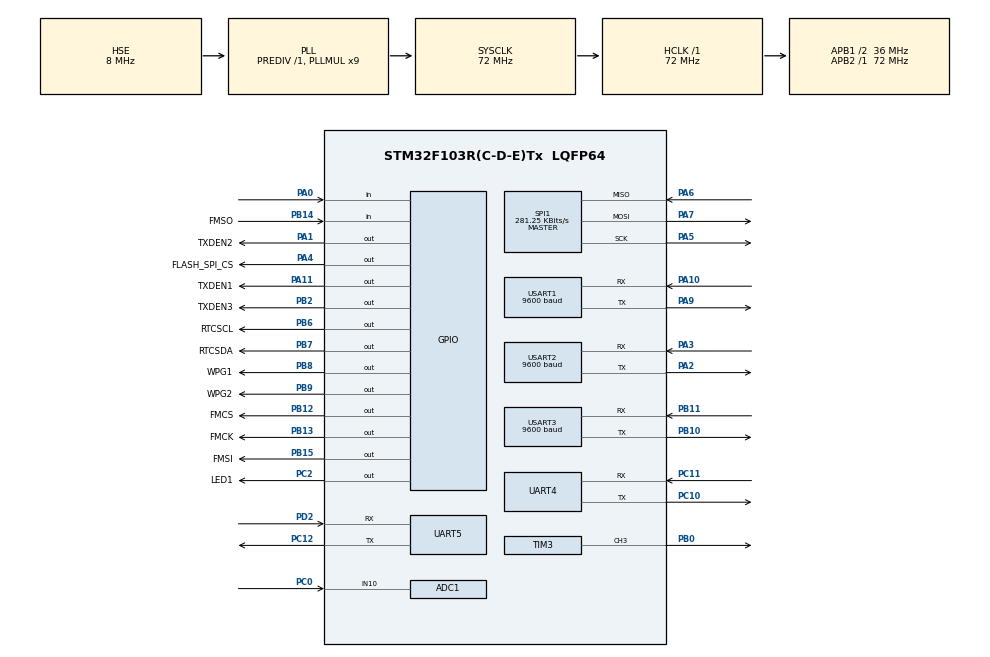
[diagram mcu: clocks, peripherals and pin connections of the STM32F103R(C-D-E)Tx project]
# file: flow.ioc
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ADC1.Channel-0\#ChannelRegularConversion=ADC_CHANNEL_10
ADC1.NbrOfConversionFlag=1
ADC1.Rank-0\#ChannelRegularConversion=1
ADC1.SamplingTime-0\#ChannelRegularConversion=ADC_SAMPLETIME_1CYCLE_5
ADC1.master=1
FATFS._CODE_PAGE=936
FATFS._USE_LFN=2
FREERTOS.Tasks01=Task01,0,512,StartTask01,Default,NULL,Dynamic,NULL,NULL;Task02,0,128,StartTask02,Default,NULL,Dynamic,NULL,NULL;Task03,0,128,StartTask03,Default,NULL,Dynamic,NULL,NULL;Task04,0,128,StartTask04,Default,NULL,Dynamic,NULL,NULL;Task05,0,256,StartTask05,Default,NULL,Dynamic,NULL,NULL;Task06,0,128,StartTask06,Default,NULL,Dynamic,NULL,NULL;Task07,0,128,StartTask07,Default,NULL,Dynamic,NULL,NULL
FREERTOS.configTOTAL_HEAP_SIZE=8192
Mcu.Family=STM32F1
Mcu.Name=STM32F103R(C-D-E)Tx
Mcu.Package=LQFP64
NVIC.PriorityGroup=NVIC_PRIORITYGROUP_4
NVIC.TIM6_IRQn=true\:5\:0\:false\:false\:true\:true\:true\:true
NVIC.TIM7_IRQn=true\:0\:0\:false\:false\:true\:false\:false\:true
NVIC.TimeBase=TIM7_IRQn
NVIC.TimeBaseIP=TIM7
NVIC.UART4_IRQn=true\:5\:0\:false\:false\:true\:true\:true\:true
NVIC.UART5_IRQn=true\:5\:0\:false\:false\:true\:true\:true\:true
NVIC.USART1_IRQn=true\:5\:0\:false\:false\:true\:true\:true\:true
NVIC.USART2_IRQn=true\:5\:0\:false\:false\:true\:true\:true\:true
NVIC.USART3_IRQn=true\:5\:0\:false\:false\:true\:true\:true\:true
PA0-WKUP.Signal=GPIO_Input
PA1.GPIO_Label=TXDEN2
PA1.GPIO_ModeDefaultOutputPP=GPIO_MODE_OUTPUT_PP
PA1.GPIO_PuPd=GPIO_NOPULL
PA1.GPIO_Speed=GPIO_SPEED_FREQ_HIGH
PA1.PinState=GPIO_PIN_RESET
PA1.Signal=GPIO_Output
PA10.Mode=Asynchronous
PA10.Signal=USART1_RX
PA11.GPIO_Label=TXDEN1
PA11.GPIO_ModeDefaultOutputPP=GPIO_MODE_OUTPUT_PP
PA11.GPIO_PuPd=GPIO_NOPULL
PA11.GPIO_Speed=GPIO_SPEED_FREQ_HIGH
PA11.PinState=GPIO_PIN_RESET
PA11.Signal=GPIO_Output
PA13.Mode=Serial_Wire
PA13.Signal=SYS_JTMS-SWDIO
PA14.Mode=Serial_Wire
PA14.Signal=SYS_JTCK-SWCLK
PA2.Mode=Asynchronous
PA2.Signal=USART2_TX
PA3.Mode=Asynchronous
PA3.Signal=USART2_RX
PA4.GPIO_Label=FLASH_SPI_CS
PA4.Signal=GPIO_Output
PA5.Mode=Full_Duplex_Master
PA5.Signal=SPI1_SCK
PA6.Mode=Full_Duplex_Master
PA6.Signal=SPI1_MISO
PA7.Mode=Full_Duplex_Master
PA7.Signal=SPI1_MOSI
PA9.Mode=Asynchronous
PA9.Signal=USART1_TX
PB0.Signal=S_TIM3_CH3
PB10.Mode=Asynchronous
PB10.Signal=USART3_TX
PB11.Mode=Asynchronous
PB11.Signal=USART3_RX
PB12.GPIO_Label=FMCS
PB12.GPIO_ModeDefaultOutputPP=GPIO_MODE_OUTPUT_PP
PB12.GPIO_PuPd=GPIO_NOPULL
PB12.GPIO_Speed=GPIO_SPEED_FREQ_HIGH
PB12.PinState=GPIO_PIN_RESET
PB12.Signal=GPIO_Output
PB13.GPIO_Label=FMCK
PB13.GPIO_ModeDefaultOutputPP=GPIO_MODE_OUTPUT_PP
PB13.GPIO_PuPd=GPIO_NOPULL
PB13.GPIO_Speed=GPIO_SPEED_FREQ_HIGH
PB13.PinState=GPIO_PIN_RESET
PB13.Signal=GPIO_Output
PB14.GPIO_Label=FMSO
PB14.GPIO_PuPd=GPIO_PULLUP
PB14.Signal=GPIO_Input
PB15.GPIO_Label=FMSI
PB15.GPIO_Speed=GPIO_SPEED_FREQ_HIGH
PB15.PinState=GPIO_PIN_RESET
PB15.Signal=GPIO_Output
PB2.GPIO_Label=TXDEN3
PB2.GPIO_ModeDefaultOutputPP=GPIO_MODE_OUTPUT_PP
PB2.GPIO_PuPd=GPIO_NOPULL
PB2.GPIO_Speed=GPIO_SPEED_FREQ_HIGH
PB2.PinState=GPIO_PIN_RESET
PB2.Signal=GPIO_Output
PB6.GPIO_Label=RTCSCL
PB6.GPIO_Speed=GPIO_SPEED_FREQ_HIGH
PB6.Signal=GPIO_Output
PB7.GPIO_Label=RTCSDA
PB7.GPIO_ModeDefaultOutputPP=GPIO_MODE_OUTPUT_OD
PB7.GPIO_PuPd=GPIO_PULLUP
PB7.GPIO_Speed=GPIO_SPEED_FREQ_HIGH
PB7.Signal=GPIO_Output
PB8.GPIO_Label=WPG1
PB8.GPIO_ModeDefaultOutputPP=GPIO_MODE_OUTPUT_PP
PB8.GPIO_PuPd=GPIO_NOPULL
PB8.GPIO_Speed=GPIO_SPEED_FREQ_HIGH
PB8.PinState=GPIO_PIN_RESET
PB8.Signal=GPIO_Output
PB9.GPIO_Label=WPG2
PB9.GPIO_ModeDefaultOutputPP=GPIO_MODE_OUTPUT_PP
PB9.GPIO_PuPd=GPIO_NOPULL
PB9.GPIO_Speed=GPIO_SPEED_FREQ_HIGH
PB9.PinState=GPIO_PIN_RESET
PB9.Signal=GPIO_Output
PC0.Signal=ADCx_IN10
PC10.Mode=Asynchronous
PC10.Signal=UART4_TX
PC11.Mode=Asynchronous
PC11.Signal=UART4_RX
PC12.Mode=Asynchronous
PC12.Signal=UART5_TX
PC2.GPIO_Label=LED1
PC2.GPIO_ModeDefaultOutputPP=GPIO_MODE_OUTPUT_PP
PC2.GPIO_PuPd=GPIO_NOPULL
PC2.GPIO_Speed=GPIO_SPEED_FREQ_HIGH
PC2.PinState=GPIO_PIN_RESET
PC2.Signal=GPIO_Output
PD0-OSC_IN.Mode=HSE-External-Oscillator
PD0-OSC_IN.Signal=RCC_OSC_IN
PD1-OSC_OUT.Mode=HSE-External-Oscillator
PD1-OSC_OUT.Signal=RCC_OSC_OUT
PD2.Mode=Asynchronous
PD2.Signal=UART5_RX
ProjectManager.HeapSize=0x200
ProjectManager.StackSize=0x1000
ProjectManager.TargetToolchain=MDK-ARM V5.27
RCC.ADCPresc=RCC_ADCPCLK2_DIV6
RCC.AHBFreq_Value=72000000
RCC.APB1CLKDivider=RCC_HCLK_DIV2
RCC.APB1Freq_Value=36000000
RCC.APB1TimFreq_Value=72000000
RCC.APB2Freq_Value=72000000
RCC.APB2TimFreq_Value=72000000
RCC.HCLKFreq_Value=72000000
RCC.PLLMUL=RCC_PLL_MUL9
RCC.PLLSourceVirtual=RCC_PLLSOURCE_HSE
RCC.SYSCLKFreq_VALUE=72000000
RCC.SYSCLKSource=RCC_SYSCLKSOURCE_PLLCLK
RCC.USBFreq_Value=72000000
SH.ADCx_IN10.0=ADC1_IN10,IN10
SH.S_TIM3_CH3.0=TIM3_CH3,PWM Generation3 CH3
SPI1.BaudRatePrescaler=SPI_BAUDRATEPRESCALER_256
SPI1.CLKPolarity=SPI_POLARITY_HIGH
SPI1.CalculateBaudRate=281.25 KBits/s
SPI1.Direction=SPI_DIRECTION_2LINES
SPI1.Mode=SPI_MODE_MASTER
SPI1.VirtualType=VM_MASTER
TIM3.Channel-PWM\ Generation3\ CH3=TIM_CHANNEL_3
TIM3.Period=20000-1
TIM3.Prescaler=36-1
TIM6.Period=10000-1
TIM6.Prescaler=72-1
UART4.VirtualMode=Asynchronous
UART5.VirtualMode=Asynchronous
USART1.BaudRate=9600
USART1.VirtualMode=VM_ASYNC
USART2.BaudRate=9600
USART2.VirtualMode=VM_ASYNC
USART3.BaudRate=9600
USART3.VirtualMode=VM_ASYNC
VP_CRC_VS_CRC.Mode=CRC_Activate
VP_FATFS_VS_Generic.Mode=User_defined
VP_FREERTOS_VS_CMSIS_V1.Mode=CMSIS_V1
VP_SYS_VS_tim7.Mode=TIM7
VP_TIM3_VS_ClockSourceINT.Mode=Internal
VP_TIM6_VS_ClockSourceINT.Mode=Enable_Timer
board=custom

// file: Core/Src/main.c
/* USER CODE BEGIN Header */
/**
  ******************************************************************************
  * @file           : main.c
  * @brief          : Main program body
  ******************************************************************************
  * @attention
  *
  * <h2><center>&copy; Copyright (c) 2021 STMicroelectronics.
  * All rights reserved.</center></h2>
  *
  * This software component is licensed by ST under Ultimate Liberty license
  * SLA0044, the "License"; You may not use this file except in compliance with
  * the License. You may obtain a copy of the License at:
  *                             www.st.com/SLA0044
  *
  ******************************************************************************
  */
/* USER CODE END Header */
#include "main.h"
#include "cmsis_os.h"
#include "adc.h"
#include "crc.h"
#include "fatfs.h"
#include "spi.h"
#include "tim.h"
#include "usart.h"
#include "gpio.h"

void SystemClock_Config(void);
void MX_FREERTOS_Init(void);

int main(void)
{

  /* MCU Configuration--------------------------------------------------------*/

  /* Reset of all peripherals, Initializes the Flash interface and the Systick. */
  HAL_Init();

  /* Configure the system clock */
  SystemClock_Config();

  /* Initialize all configured peripherals */
  MX_GPIO_Init();
  MX_ADC1_Init();
  MX_SPI1_Init();
  MX_TIM3_Init();
  MX_UART4_Init();
  MX_UART5_Init();
  MX_USART1_UART_Init();
  MX_USART2_UART_Init();
  MX_USART3_UART_Init();
  MX_FATFS_Init();
  MX_CRC_Init();
  MX_TIM6_Init();

  /* Call init function for freertos objects (in freertos.c) */
  MX_FREERTOS_Init();
  /* Start scheduler */
  osKernelStart();

  /* We should never get here as control is now taken by the scheduler */
  /* Infinite loop */
  while (1)
  {

  }
}

void SystemClock_Config(void)
{
  RCC_OscInitTypeDef RCC_OscInitStruct = {0};
  RCC_ClkInitTypeDef RCC_ClkInitStruct = {0};
  RCC_PeriphCLKInitTypeDef PeriphClkInit = {0};

  /** Initializes the RCC Oscillators according to the specified parameters
  * in the RCC_OscInitTypeDef structure.
  */
  RCC_OscInitStruct.OscillatorType = RCC_OSCILLATORTYPE_HSE;
  RCC_OscInitStruct.HSEState = RCC_HSE_ON;
  RCC_OscInitStruct.HSEPredivValue = RCC_HSE_PREDIV_DIV1;
  RCC_OscInitStruct.HSIState = RCC_HSI_ON;
  RCC_OscInitStruct.PLL.PLLState = RCC_PLL_ON;
  RCC_OscInitStruct.PLL.PLLSource = RCC_PLLSOURCE_HSE;
  RCC_OscInitStruct.PLL.PLLMUL = RCC_PLL_MUL9;
  if (HAL_RCC_OscConfig(&RCC_OscInitStruct) != HAL_OK)
  {
    Error_Handler();
  }
  /** Initializes the CPU, AHB and APB buses clocks
  */
  RCC_ClkInitStruct.ClockType = RCC_CLOCKTYPE_HCLK|RCC_CLOCKTYPE_SYSCLK
                              |RCC_CLOCKTYPE_PCLK1|RCC_CLOCKTYPE_PCLK2;
  RCC_ClkInitStruct.SYSCLKSource = RCC_SYSCLKSOURCE_PLLCLK;
  RCC_ClkInitStruct.AHBCLKDivider = RCC_SYSCLK_DIV1;
  RCC_ClkInitStruct.APB1CLKDivider = RCC_HCLK_DIV2;
  RCC_ClkInitStruct.APB2CLKDivider = RCC_HCLK_DIV1;

  if (HAL_RCC_ClockConfig(&RCC_ClkInitStruct, FLASH_LATENCY_2) != HAL_OK)
  {
    Error_Handler();
  }
  PeriphClkInit.PeriphClockSelection = RCC_PERIPHCLK_ADC;
  PeriphClkInit.AdcClockSelection = RCC_ADCPCLK2_DIV6;
  if (HAL_RCCEx_PeriphCLKConfig(&PeriphClkInit) != HAL_OK)
  {
    Error_Handler();
  }
}

void HAL_TIM_PeriodElapsedCallback(TIM_HandleTypeDef *htim)
{
  if (htim->Instance == TIM7) {
    HAL_IncTick();
  }
}

void Error_Handler(void)
{
}

/************************ (C) COPYRIGHT STMicroelectronics *****END OF FILE****/

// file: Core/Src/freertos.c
/* USER CODE BEGIN Header */
/**
  ******************************************************************************
  * File Name          : freertos.c
  * Description        : Code for freertos applications
  ******************************************************************************
  * @attention
  *
  * <h2><center>&copy; Copyright (c) 2021 STMicroelectronics.
  * All rights reserved.</center></h2>
  *
  * This software component is licensed by ST under Ultimate Liberty license
  * SLA0044, the "License"; You may not use this file except in compliance with
  * the License. You may obtain a copy of the License at:
  *                             www.st.com/SLA0044
  *
  ******************************************************************************
  */
/* USER CODE END Header */

#include "FreeRTOS.h"
#include "task.h"
#include "main.h"
#include "cmsis_os.h"

/* USER CODE BEGIN Includes */
#include "Task01.h"
#include "Task02.h"
#include "Task03.h"
#include "Task04.h"
#include "Task05.h"
#include "Task06.h"
#include "Task07.h"
/* USER CODE END Includes */

osThreadId Task01Handle;
osThreadId Task02Handle;
osThreadId Task03Handle;
osThreadId Task04Handle;
osThreadId Task05Handle;
osThreadId Task06Handle;
osThreadId Task07Handle;

void StartTask01(void const * argument);
void StartTask02(void const * argument);
void StartTask03(void const * argument);
void StartTask04(void const * argument);
void StartTask05(void const * argument);
void StartTask06(void const * argument);
void StartTask07(void const * argument);

void MX_FREERTOS_Init(void); /* (MISRA C 2004 rule 8.1) */

/* GetIdleTaskMemory prototype (linked to static allocation support) */
void vApplicationGetIdleTaskMemory( StaticTask_t **ppxIdleTaskTCBBuffer, StackType_t **ppxIdleTaskStackBuffer, uint32_t *pulIdleTaskStackSize );

/* USER CODE BEGIN GET_IDLE_TASK_MEMORY */
static StaticTask_t xIdleTaskTCBBuffer;
static StackType_t xIdleStack[configMINIMAL_STACK_SIZE];

void vApplicationGetIdleTaskMemory( StaticTask_t **ppxIdleTaskTCBBuffer, StackType_t **ppxIdleTaskStackBuffer, uint32_t *pulIdleTaskStackSize )
{
  *ppxIdleTaskTCBBuffer = &xIdleTaskTCBBuffer;
  *ppxIdleTaskStackBuffer = &xIdleStack[0];
  *pulIdleTaskStackSize = configMINIMAL_STACK_SIZE;
  /* place for user code */
}
/* USER CODE END GET_IDLE_TASK_MEMORY */

void MX_FREERTOS_Init(void) {

  /* Create the thread(s) */
  /* definition and creation of Task01 */
  osThreadDef(Task01, StartTask01, osPriorityNormal, 0, 512);
  Task01Handle = osThreadCreate(osThread(Task01), NULL);

  /* definition and creation of Task02 */
  osThreadDef(Task02, StartTask02, osPriorityNormal, 0, 128);
  Task02Handle = osThreadCreate(osThread(Task02), NULL);

  /* definition and creation of Task03 */
  osThreadDef(Task03, StartTask03, osPriorityNormal, 0, 128);
  Task03Handle = osThreadCreate(osThread(Task03), NULL);

  /* definition and creation of Task04 */
  osThreadDef(Task04, StartTask04, osPriorityNormal, 0, 256);
  Task04Handle = osThreadCreate(osThread(Task04), NULL);

  /* definition and creation of Task05 */
  osThreadDef(Task05, StartTask05, osPriorityNormal, 0, 256);
  Task05Handle = osThreadCreate(osThread(Task05), NULL);

  /* definition and creation of Task06 */
  osThreadDef(Task06, StartTask06, osPriorityNormal, 0, 128);
  Task06Handle = osThreadCreate(osThread(Task06), NULL);

  /* definition and creation of Task07 */
  osThreadDef(Task07, StartTask07, osPriorityNormal, 0, 128);
  Task07Handle = osThreadCreate(osThread(Task07), NULL);

}

void StartTask01(void const * argument)
{
  /* USER CODE BEGIN StartTask01 */
  /* Infinite loop */
  for(;;)
  {
		Task01Main();
    osDelay(1);
  }
  /* USER CODE END StartTask01 */
}

void StartTask02(void const * argument)
{
  /* USER CODE BEGIN StartTask02 */
  /* Infinite loop */
  for(;;)
  {
		Task02Main();
    osDelay(1);
  }
  /* USER CODE END StartTask02 */
}

void StartTask03(void const * argument)
{
  /* USER CODE BEGIN StartTask03 */
  /* Infinite loop */
  for(;;)
  {
		Task03Main();
    osDelay(1);
  }
  /* USER CODE END StartTask03 */
}

void StartTask04(void const * argument)
{
  /* USER CODE BEGIN StartTask04 */
  /* Infinite loop */
  for(;;)
  {
		Task04Main();
    osDelay(1);
  }
  /* USER CODE END StartTask04 */
}

void StartTask05(void const * argument)
{
  /* USER CODE BEGIN StartTask05 */
  /* Infinite loop */
  for(;;)
  {
		Task05Main();
    osDelay(1);
  }
  /* USER CODE END StartTask05 */
}

void StartTask06(void const * argument)
{
  /* USER CODE BEGIN StartTask06 */
  /* Infinite loop */
  for(;;)
  {
		Task06Main();
    osDelay(1);
  }
  /* USER CODE END StartTask06 */
}

void StartTask07(void const * argument)
{
  /* USER CODE BEGIN StartTask07 */
  /* Infinite loop */
  for(;;)
  {
		Task07Main();
    osDelay(1);
  }
  /* USER CODE END StartTask07 */
}

/************************ (C) COPYRIGHT STMicroelectronics *****END OF FILE****/
